# Template register map
Vendor: VendorName Co.Ltd; Series: SeriesName; File version: 1.2
CPU: CM7 r0p1, little endian, MPU, FPU, 4 interrupt priority bits
Registers are 32-bit, read-write, no defined reset value unless marked. A register's access mark holds for its fields unless they carry their own. Offsets are from the block's base; [hi:lo] are bit positions; {n}, {i} and the like mark numbered series.

## SPI1 — Serial Peripheral Interface 1
Base 0x40046000
Same registers: SPI2 0x40047000, SPI3 0x40062000, SPI4 0x4006D000
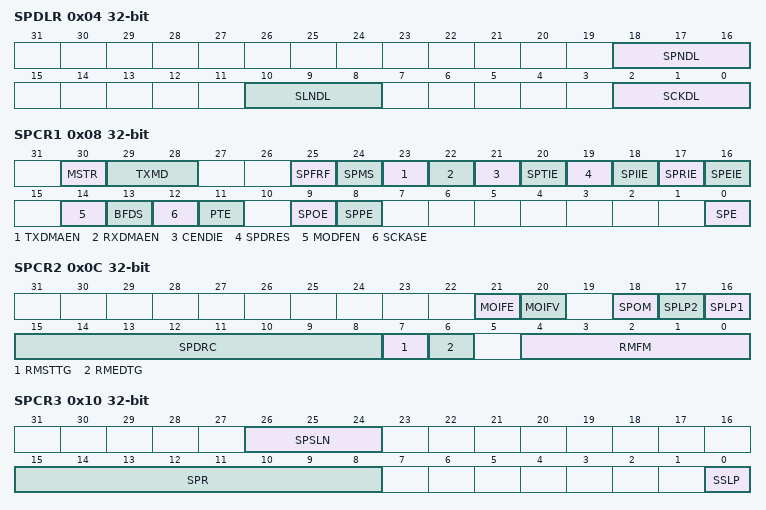
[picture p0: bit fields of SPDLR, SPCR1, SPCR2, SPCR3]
0x04 SPDLR — SPI delay register
  [18:16] SPNDL — SPI SPNDL[2:0] bit: SPI next visit delay
  [10:8] SLNDL — SPI SLNDL[2:0] bit: SPI_NSS signal invalid delay
  [2:0] SCKDL — SPI SCKDL[2:0] bit: SPI clock delay time
0x08 SPCR1 — SPI control register 1
  [30] MSTR — SPI MSTR bit: SPI master or slave mode select
  [29:28] TXMD — SPI TXMD[1:0] bit: communication operating mode select
  [25] SPFRF — SPI SPFRF bit: SPI failure receive buffer full
  [24] SPMS — SPI SPMS bit: SPI mode select
  [23] TXDMAEN — SPI TXDMAEN bit: transmit finished start DMA enable
  [22] RXDMAEN — SPI RXDMAEN bit: receive finished start DMA enable
  [21] CENDIE — SPI CENDIE bit: communication end interruption enable
  [20] SPTIE — SPI SPTIE bit: transmit buffer empty interrupt enable
  [19] SPDRES — SPI SPDRES bit: interrupt request
  [18] SPIIE — SPI SPIIE bit: SPI idle interrupt enable
  [17] SPRIE — SPI SPRIE bit: SPI receive buffer full interrupt enable
  [16] SPEIE — SPI SPEIE bit: SPI error interrupt enable
  [14] MODFEN — SPI MODFEN bit: mode fault error detection enable
  [13] BFDS — SPI BFDS bit: whether insert the delay between frames
  [12] SCKASE — SPI SCKASE bit: SPI_CLK autostop function enable
  [11] PTE — SPI PTE bit: parity check self diagnosis function start
  [9] SPOE — SPI SPOE bit: parity check mode
  [8] SPPE — SPI SPPE bit: parity check enable
  [0] SPE — SPI SPE bit: SPI function enable
0x0C SPCR2 — SPI control register 2
  [21] MOIFE — SPI MOIFE bit: SPI_SIMO idle fixed value enable
  [20] MOIFV — SPI MOIFV bit: SPI_SIMO idle fixed value
  [18] SPOM — SPI SPOM bit: SPI output mode select
  [17] SPLP2 — SPI SPLP2 bit: loopback mode 2
  [16] SPLP1 — SPI SPLP1 bit: loopback mode 1
  [15:8] SPDRC — SPI SPDRC[7:0] bit: receive data ready
  [7] RMSTTG wo — SPI RMSTTG bit: start receive
  [6] RMEDTG wo — SPI RMEDTG bit: end receive
  [4:0] RMFM — SPI RMFM[4:0] bit: the number of frames that can be received and adjusted
0x10 SPCR3 — SPI control register 3
  [26:24] SPSLN — SPI SPSLN[2:0] bit: sequence length
  [15:8] SPR — SPI SPR[7:0] bit: set period of SPI_CLK
  [0] SSLP — SPI SSLP bit: SPI_NSS signal polarity
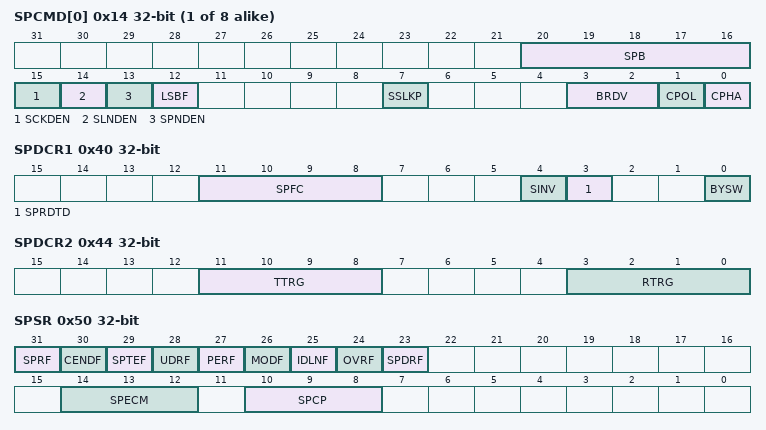
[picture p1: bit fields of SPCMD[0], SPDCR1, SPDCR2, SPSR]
{0x14+4i} SPCMD[{i}] (i=0..7) — Grouping of SPCMD0~SPCMD7
  [20:16] SPB — SPI SPB[4:0] bit: SPI data length setting
  [15] SCKDEN — SPI SCKDEN bit: RSPCK delay setting enable
  [14] SLNDEN — SPI SLNDEN bit: SSL Negation delay setting enable
  [13] SPNDEN — SPI SPNDEN bit: SPI next-access delay enable
  [12] LSBF — SPI LSBF bit: SPI LSB first
  [7] SSLKP — SPI SSLKP bit: SSL signal level keeping
  [3:2] BRDV — SPI BRDV[1:0] bit: bit rate division setting
  [1] CPOL — SPI CPOL bit: RSPCK polarity setting
  [0] CPHA — SPI CPHA bit: RSPCK phase setting
0x40 SPDCR1 — SPI data control register 1
  [11:8] SPFC — SPI SPFC[3:0] bit: number of frames specification
  [4] SINV — SPI SINV bit: serial data inversion
  [3] SPRDTD — SPI SPRDTD bit: SPI receive or transmit data select
  [0] BYSW — SPI BYSW bit: bytes switch
0x44 SPDCR2 — SPI data control register 2
  [11:8] TTRG — SPI TTRG[3:0] bit: threshold setting for the empty number
  [3:0] RTRG — SPI RTRG[3:0] bit: threshold setting for the number of stored data
0x50 SPSR ro — SPI satus register
  [31] SPRF — SPI SPRF bit: SPI receive buffer full flag
  [30] CENDF — SPI CENDF bit: communication end interrupt flag
  [29] SPTEF — SPI SPTEF bit: SPI transmit buffer empty flag
  [28] UDRF — SPI UDRF bit: underrun error flag
  [27] PERF — SPI PERF bit: parity error flag
  [26] MODF — SPI MODF bit: mode fault error flag
  [25] IDLNF — SPI IDLNF bit: SPI idle flag
  [24] OVRF — SPI OVRF bit: overrun error flag
  [23] SPDRF — SPI SPDRF bit: receive data ready flag
  [14:12] SPECM — SPI SPECM[2:0] bit: error command status
  [10:8] SPCP — SPI SPCP[2:0] bit: command pointer CMD0~7
0x58 SPTFSR ro — SPI transmit FIFO status register
  [4:0] TFDN — SPI TFDN[4:0] bit: the number of transmitting buffer FIFO data vacancy
0x5C SPRFSR ro — SPI receive FIFO status register
  [4:0] RFDN — SPI RFDN[4:0] bit: the number of receiving buffer FIFO data storage
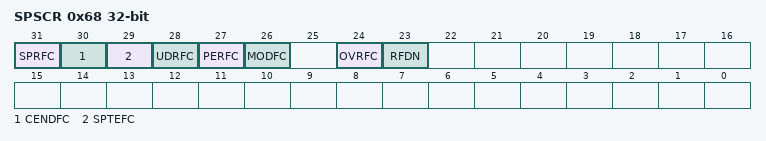
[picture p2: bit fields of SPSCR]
0x68 SPSCR wo — SPI status clear register
  [31] SPRFC — SPI SPRFC bit: SPI receive buffer full clear flag
  [30] CENDFC — SPI CENDFC bit: communication end clear flag
  [29] SPTEFC — SPI SPTEFC bit: SPI transmit buffer empty clear flag
  [28] UDRFC — SPI UDRFC bit: underload error clear flag
  [27] PERFC — SPI PERFC bit: parity check error clear flag
  [26] MODFC — SPI MODFC bit: mode failure clear flag
  [24] OVRFC — SPI OVRFC bit: overload error clear flag
  [23] RFDN — SPI RFDN bit: receive ready clear flag
0x6C SPFCR wo — SPI FIFO clear register
  [0] SPFRST — SPI SPFRST bit: SPI FIFO clear
